# MCXC444 register map
Vendor: NXP Semiconductors; Series: MCX; File version: 1.6
CPU: CM0PLUS r0p0, little endian, no MPU, no FPU, VTOR, 2 interrupt priority bits
Registers are 32-bit, read-write, reset 0x0 unless marked. A register's access mark holds for its fields unless they carry their own. Offsets are from the block's base; [hi:lo] are bit positions; 'fields as' and 'values as' point back to an identical list.

## SPI0 — Serial Peripheral Interface
Base 0x40076000; register names take the prefix SPI0_
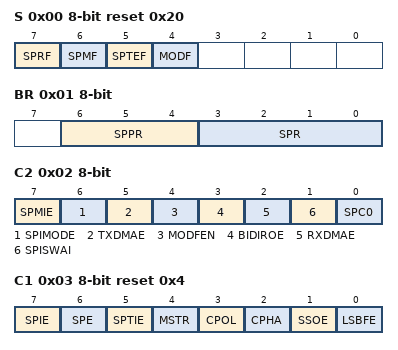
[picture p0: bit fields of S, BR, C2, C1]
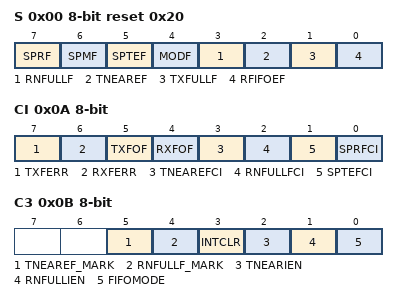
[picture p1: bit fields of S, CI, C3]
0x00 S 8-bit reset 0x20 — SPI Status Register
  [7] SPRF ro — SPI Read Buffer Full Flag (when FIFO is not supported or not enabled) or SPI read FIFO FULL flag (when FIFO is supported and enabled)
    0=b0 (No data available in the receive data buffer (when FIFOMODE is not present or is 0) or Read FIFO is not full (when FIFOMODE is 1)); 1=b1 (Data available in the receive data buffer (when FIFOMODE is not present or is 0) or Read FIFO is full (when FIFOMODE is 1))
  [6] SPMF — SPI Match Flag
    0=b0 (Value in the receive data buffer does not match the value in the MH:ML registers); 1=b1 (Value in the receive data buffer matches the value in the MH:ML registers)
  [5] SPTEF ro — SPI Transmit Buffer Empty Flag (when FIFO is not supported or not enabled) or SPI transmit FIFO empty flag (when FIFO is supported and enabled)
    0=b0 (SPI transmit buffer not empty (when FIFOMODE is not present or is 0) or SPI FIFO not empty (when FIFOMODE is 1)); 1=b1 (SPI transmit buffer empty (when FIFOMODE is not present or is 0) or SPI FIFO empty (when FIFOMODE is 1))
  [4] MODF ro — Master Mode Fault Flag
    0=b0 (No mode fault error); 1=b1 (Mode fault error detected)
0x01 BR 8-bit — SPI Baud Rate Register
  [6:4] SPPR — SPI Baud Rate Prescale Divisor
    0=b000 (Baud rate prescaler divisor is 1.); 1=b001 (Baud rate prescaler divisor is 2.); 2=b010 (Baud rate prescaler divisor is 3.); 3=b011 (Baud rate prescaler divisor is 4.); 4=b100 (Baud rate prescaler divisor is 5.); 5=b101 (Baud rate prescaler divisor is 6.); 6=b110 (Baud rate prescaler divisor is 7.); 7=b111 (Baud rate prescaler divisor is 8.)
  [3:0] SPR — SPI Baud Rate Divisor
    0=b0000 (Baud rate divisor is 2.); 1=b0001 (Baud rate divisor is 4.); 2=b0010 (Baud rate divisor is 8.); 3=b0011 (Baud rate divisor is 16.); 4=b0100 (Baud rate divisor is 32.); 5=b0101 (Baud rate divisor is 64.); 6=b0110 (Baud rate divisor is 128.); 7=b0111 (Baud rate divisor is 256.); 8=b1000 (Baud rate divisor is 512.)
0x02 C2 8-bit — SPI Control Register 2
  [7] SPMIE — SPI Match Interrupt Enable
    0=b0 (Interrupts from SPMF inhibited (use polling)); 1=b1 (When SPMF is 1, requests a hardware interrupt)
  [6] SPIMODE — SPI 8-bit or 16-bit mode
    0=b0 (8-bit SPI shift register, match register, and buffers); 1=b1 (16-bit SPI shift register, match register, and buffers)
  [5] TXDMAE — Transmit DMA enable
    0=b0 (DMA request for transmit is disabled and interrupt from SPTEF is allowed); 1=b1 (DMA request for transmit is enabled and interrupt from SPTEF is disabled)
  [4] MODFEN — Master Mode-Fault Function Enable
    0=b0 (Mode fault function disabled, master SS pin reverts to general-purpose I/O not controlled by SPI); 1=b1 (Mode fault function enabled, master SS pin acts as the mode fault input or the slave select output)
  [3] BIDIROE — Bidirectional Mode Output Enable
    0=b0 (Output driver disabled so SPI data I/O pin acts as an input); 1=b1 (SPI I/O pin enabled as an output)
  [2] RXDMAE — Receive DMA enable
    0=b0 (DMA request for receive is disabled and interrupt from SPRF is allowed); 1=b1 (DMA request for receive is enabled and interrupt from SPRF is disabled)
  [1] SPISWAI — SPI Stop in Wait Mode
    0=b0 (SPI clocks continue to operate in Wait mode.); 1=b1 (SPI clocks stop when the MCU enters Wait mode.)
  [0] SPC0 — SPI Pin Control 0
    0=b0 (SPI uses separate pins for data input and data output (pin mode is normal). In master mode of operation: MISO is master in and MOSI is master out. In slave mode of operation: MISO is slave out and MOSI is slave in.); 1=b1 (SPI configured for single-wire bidirectional operation (pin mode is bidirectional). In master mode of operation: MISO is not used by SPI; MOSI is master in when BIDIROE is 0 or master I/O when BIDIROE is 1. In slave mode of operation: MISO is slave in when BIDIROE is 0 or slave I/O when BIDIROE is 1; MOSI is not used by SPI.)
0x03 C1 8-bit reset 0x4 — SPI Control Register 1
  [7] SPIE — SPI Interrupt Enable: for SPRF and MODF (when FIFO is not supported or not enabled) or for read FIFO (when FIFO is supported and enabled)
    0=b0 (Interrupts from SPRF and MODF are inhibited-use polling (when FIFOMODE is not present or is 0) or Read FIFO Full Interrupts are disabled (when FIFOMODE is 1)); 1=b1 (Request a hardware interrupt when SPRF or MODF is 1 (when FIFOMODE is not present or is 0) or Read FIFO Full Interrupts are enabled (when FIFOMODE is 1))
  [6] SPE — SPI System Enable
    0=b0 (SPI system inactive); 1=b1 (SPI system enabled)
  [5] SPTIE — SPI Transmit Interrupt Enable
    0=b0 (Interrupts from SPTEF inhibited (use polling)); 1=b1 (When SPTEF is 1, hardware interrupt requested)
  [4] MSTR — Master/Slave Mode Select
    0=b0 (SPI module configured as a slave SPI device); 1=b1 (SPI module configured as a master SPI device)
  [3] CPOL — Clock Polarity
    0=b0 (Active-high SPI clock (idles low)); 1=b1 (Active-low SPI clock (idles high))
  [2] CPHA — Clock Phase
    0=b0 (First edge on SPSCK occurs at the middle of the first cycle of a data transfer.); 1=b1 (First edge on SPSCK occurs at the start of the first cycle of a data transfer.)
  [1] SSOE — Slave Select Output Enable
    0=b0 (When C2[MODFEN] is 0: In master mode, SS pin function is general-purpose I/O (not SPI). In slave mode, SS pin function is slave select input. When C2[MODFEN] is 1: In master mode, SS pin function is SS input for mode fault. In slave mode, SS pin function is slave select input.); 1=b1 (When C2[MODFEN] is 0: In master mode, SS pin function is general-purpose I/O (not SPI). In slave mode, SS pin function is slave select input. When C2[MODFEN] is 1: In master mode, SS pin function is automatic SS output. In slave mode: SS pin function is slave select input.)
  [0] LSBFE — LSB First (shifter direction)
    0=b0 (SPI serial data transfers start with the most significant bit.); 1=b1 (SPI serial data transfers start with the least significant bit.)
0x04 ML 8-bit — SPI Match Register low
  [7:0] Bits — Hardware compare value (low byte)
0x05 MH 8-bit — SPI match register high
  [7:0] Bits — Hardware compare value (high byte)
0x06 DL 8-bit — SPI Data Register low
  [7:0] Bits — Data (low byte)
0x07 DH 8-bit — SPI data register high
  [7:0] Bits — Data (high byte)

## SPI1 — Serial Peripheral Interface
Base 0x40077000; register names take the prefix SPI1_
Registers as SPI0; these are added or differ:
0x00 S 8-bit reset 0x20 — SPI Status Register
  [7] SPRF ro — SPI Read Buffer Full Flag (when FIFO is not supported or not enabled) or SPI read FIFO FULL flag (when FIFO is supported and enabled)
    values as SPI0.S.SPRF
  [6] SPMF — SPI Match Flag
    0=b0 (Value in the receive data buffer does not match the value in the MH:ML registers); 1=b1 (Value in the receive data buffer matches the value in the MH:ML registers)
  [5] SPTEF ro — SPI Transmit Buffer Empty Flag (when FIFO is not supported or not enabled) or SPI transmit FIFO empty flag (when FIFO is supported and enabled)
    values as SPI0.S.SPTEF
  [4] MODF ro — Master Mode Fault Flag
    0=b0 (No mode fault error); 1=b1 (Mode fault error detected)
  [3] RNFULLF ro — Receive FIFO nearly full flag
    0=b0 (Receive FIFO has received less than 48 bits (when C3[RNFULLF_MARK] is 0) or less than 32 bits (when C3[RNFULLF_MARK] is 1)); 1=b1 (Receive FIFO has received data of an amount equal to or greater than 48 bits (when C3[RNFULLF_MARK] is 0) or 32 bits (when C3[RNFULLF_MARK] is 1))
  [2] TNEAREF ro — Transmit FIFO nearly empty flag
    0=b0 (Transmit FIFO has more than 16 bits (when C3[TNEAREF_MARK] is 0) or more than 32 bits (when C3[TNEAREF_MARK] is 1) remaining to transmit); 1=b1 (Transmit FIFO has an amount of data equal to or less than 16 bits (when C3[TNEAREF_MARK] is 0) or 32 bits (when C3[TNEAREF_MARK] is 1) remaining to transmit)
  [1] TXFULLF ro — Transmit FIFO full flag
    0=b0 (Transmit FIFO has less than 8 bytes); 1=b1 (Transmit FIFO has 8 bytes of data)
  [0] RFIFOEF ro — SPI read FIFO empty flag
    0=b0 (Read FIFO has data. Reads of the DH:DL registers in 16-bit mode or the DL register in 8-bit mode will empty the read FIFO.); 1=b1 (Read FIFO is empty.)
0x0A CI 8-bit — SPI clear interrupt register
  [7] TXFERR ro — Transmit FIFO error flag
    0=b0 (No transmit FIFO error occurred); 1=b1 (A transmit FIFO error occurred)
  [6] RXFERR ro — Receive FIFO error flag
    0=b0 (No receive FIFO error occurred); 1=b1 (A receive FIFO error occurred)
  [5] TXFOF ro — Transmit FIFO overflow flag
    0=b0 (Transmit FIFO overflow condition has not occurred); 1=b1 (Transmit FIFO overflow condition occurred)
  [4] RXFOF ro — Receive FIFO overflow flag
    0=b0 (Receive FIFO overflow condition has not occurred); 1=b1 (Receive FIFO overflow condition occurred)
  [3] TNEAREFCI — Transmit FIFO nearly empty flag clear interrupt
  [2] RNFULLFCI — Receive FIFO nearly full flag clear interrupt
  [1] SPTEFCI — Transmit FIFO empty flag clear interrupt
  [0] SPRFCI — Receive FIFO full flag clear interrupt
0x0B C3 8-bit — SPI control register 3
  [5] TNEAREF_MARK — Transmit FIFO nearly empty watermark
    0=b0 (TNEAREF is set when the transmit FIFO has 16 bits or less); 1=b1 (TNEAREF is set when the transmit FIFO has 32 bits or less)
  [4] RNFULLF_MARK — Receive FIFO nearly full watermark
    0=b0 (RNFULLF is set when the receive FIFO has 48 bits or more); 1=b1 (RNFULLF is set when the receive FIFO has 32 bits or more)
  [3] INTCLR — Interrupt clearing mechanism select
    0=b0 (These interrupts are cleared when the corresponding flags are cleared depending on the state of the FIFOs); 1=b1 (These interrupts are cleared by writing the corresponding bits in the CI register)
  [2] TNEARIEN — Transmit FIFO nearly empty interrupt enable
    0=b0 (No interrupt upon TNEAREF being set); 1=b1 (Enable interrupts upon TNEAREF being set)
  [1] RNFULLIEN — Receive FIFO nearly full interrupt enable
    0=b0 (No interrupt upon RNFULLF being set); 1=b1 (Enable interrupts upon RNFULLF being set)
  [0] FIFOMODE — FIFO mode enable
    0=b0 (Buffer mode disabled); 1=b1 (Data available in the receive data buffer)
